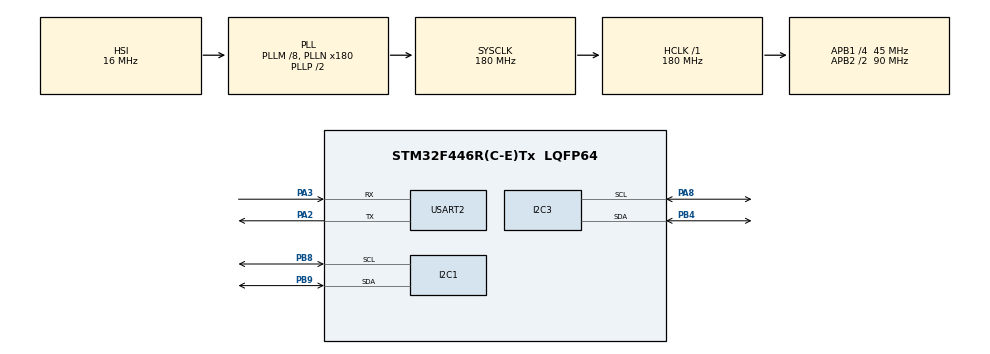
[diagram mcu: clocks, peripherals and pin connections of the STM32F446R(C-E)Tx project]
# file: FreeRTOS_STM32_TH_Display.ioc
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I2C3.I2C_Mode=I2C_Fast
Mcu.Family=STM32F4
Mcu.Name=STM32F446R(C-E)Tx
Mcu.Package=LQFP64
NVIC.PriorityGroup=NVIC_PRIORITYGROUP_4
NVIC.TIM6_DAC_IRQn=true\:15\:0\:false\:false\:true\:false\:true\:true
NVIC.TimeBase=TIM6_DAC_IRQn
NVIC.TimeBaseIP=TIM6
PA13.Mode=Serial_Wire
PA13.Signal=SYS_JTMS-SWDIO
PA14.Mode=Serial_Wire
PA14.Signal=SYS_JTCK-SWCLK
PA2.Mode=Asynchronous
PA2.Signal=USART2_TX
PA3.Mode=Asynchronous
PA3.Signal=USART2_RX
PA8.Mode=I2C
PA8.Signal=I2C3_SCL
PB4.Mode=I2C
PB4.Signal=I2C3_SDA
PB8.GPIO_Pu=GPIO_PULLUP
PB8.Mode=I2C
PB8.Signal=I2C1_SCL
PB9.GPIO_Pu=GPIO_PULLUP
PB9.Mode=I2C
PB9.Signal=I2C1_SDA
PH0-OSC_IN.Mode=HSE-External-Clock-Source
PH0-OSC_IN.Signal=RCC_OSC_IN
PH1-OSC_OUT.Mode=HSE-External-Clock-Source
PH1-OSC_OUT.Signal=RCC_OSC_OUT
ProjectManager.HeapSize=0x200
ProjectManager.StackSize=0x400
ProjectManager.TargetToolchain=STM32CubeIDE
RCC.AHBFreq_Value=180000000
RCC.APB1CLKDivider=RCC_HCLK_DIV4
RCC.APB1Freq_Value=45000000
RCC.APB1TimFreq_Value=90000000
RCC.APB2CLKDivider=RCC_HCLK_DIV2
RCC.APB2Freq_Value=90000000
RCC.APB2TimFreq_Value=180000000
RCC.CortexFreq_Value=180000000
RCC.HCLKFreq_Value=180000000
RCC.PLLM=8
RCC.PLLN=180
RCC.SYSCLKFreq_VALUE=180000000
RCC.SYSCLKSource=RCC_SYSCLKSOURCE_PLLCLK
RCC.USBFreq_Value=180000000
RCC.VCOOutputFreq_Value=360000000
USART2.VirtualMode=VM_ASYNC
VP_SYS_VS_tim6.Mode=TIM6
board=custom

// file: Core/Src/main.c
/* USER CODE BEGIN Header */
/**
  ******************************************************************************
  * @file           : main.c
  * @brief          : Main program body
  ******************************************************************************
  * @attention
  *
  * Copyright (c) 2026 STMicroelectronics.
  * All rights reserved.
  *
  * This software is licensed under terms that can be found in the LICENSE file
  * in the root directory of this software component.
  * If no LICENSE file comes with this software, it is provided AS-IS.
  *
  ******************************************************************************
  */
/* USER CODE END Header */
#include "main.h"

/* USER CODE BEGIN Includes */

#include "task_handler.h"
/* USER CODE END Includes */

/* USER CODE BEGIN PTD */
	/* Global FreeRTOS Message Queue handle shared across producer/consumer tasks */
	QueueHandle_t xSensorQueue = NULL;
/* USER CODE END PTD */

I2C_HandleTypeDef hi2c1;
I2C_HandleTypeDef hi2c3;

UART_HandleTypeDef huart2;

void SystemClock_Config(void);
static void MX_GPIO_Init(void);
static void MX_I2C1_Init(void);
static void MX_I2C3_Init(void);
static void MX_USART2_UART_Init(void);

int main(void)
{

  /* MCU Configuration--------------------------------------------------------*/

  /* Reset of all peripherals, Initializes the Flash interface and the Systick. */
  HAL_Init();

  /* Configure the system clock */
  SystemClock_Config();

  /* Initialize all configured peripherals */
  MX_GPIO_Init();
  MX_I2C1_Init();
  MX_I2C3_Init();
  MX_USART2_UART_Init();
  /* USER CODE BEGIN 2 */
  /* 1. Initialize external I2C devices (SSD1306 on I2C3, HDC1080 on I2C1)*/
  	init_OLED();
    init_HDC1080();

    /* 2. Create Message Queue capable of holding 10 SensorMsg_t items */
    xSensorQueue = xQueueCreate(10, sizeof(SensorMsg_t));
    configASSERT(xSensorQueue != NULL);

    /* 3. Create Periodic FreeRTOS Tasks:
         *    - TempTask (Priority 3): Runs 1st every 1000 ms
         *    - HumTask  (Priority 2): Runs 2nd every 1000 ms
         *    - DispTask (Priority 1): Runs 3rd every 500 ms (512 words stack for snprintf float) */
    BaseType_t status;

    status =xTaskCreate(vTempTask, "TempTask", 256, NULL, 3, NULL);
    configASSERT(status == pdPASS);

    status =xTaskCreate(vHumidityTask, "HumTask", 256, NULL, 2, NULL);
    configASSERT(status == pdPASS);

    status =xTaskCreate(vDisplayTask, "DispTask", 512, NULL, 1, NULL);
    configASSERT(status == pdPASS);

    /* Start FreeRTOS Preemptive Scheduler */
    vTaskStartScheduler();
  /* USER CODE END 2 */

  /* Infinite loop */
  while (1)
  {

  }
}

void SystemClock_Config(void)
{
  RCC_OscInitTypeDef RCC_OscInitStruct = {0};
  RCC_ClkInitTypeDef RCC_ClkInitStruct = {0};

  /** Configure the main internal regulator output voltage
  */
  __HAL_RCC_PWR_CLK_ENABLE();
  __HAL_PWR_VOLTAGESCALING_CONFIG(PWR_REGULATOR_VOLTAGE_SCALE1);

  /** Initializes the RCC Oscillators according to the specified parameters
  * in the RCC_OscInitTypeDef structure.
  */
  RCC_OscInitStruct.OscillatorType = RCC_OSCILLATORTYPE_HSI;
  RCC_OscInitStruct.HSIState = RCC_HSI_ON;
  RCC_OscInitStruct.HSICalibrationValue = RCC_HSICALIBRATION_DEFAULT;
  RCC_OscInitStruct.PLL.PLLState = RCC_PLL_ON;
  RCC_OscInitStruct.PLL.PLLSource = RCC_PLLSOURCE_HSI;
  RCC_OscInitStruct.PLL.PLLM = 8;
  RCC_OscInitStruct.PLL.PLLN = 180;
  RCC_OscInitStruct.PLL.PLLP = RCC_PLLP_DIV2;
  RCC_OscInitStruct.PLL.PLLQ = 2;
  RCC_OscInitStruct.PLL.PLLR = 2;
  if (HAL_RCC_OscConfig(&RCC_OscInitStruct) != HAL_OK)
  {
    Error_Handler();
  }

  /** Activate the Over-Drive mode
  */
  if (HAL_PWREx_EnableOverDrive() != HAL_OK)
  {
    Error_Handler();
  }

  /** Initializes the CPU, AHB and APB buses clocks
  */
  RCC_ClkInitStruct.ClockType = RCC_CLOCKTYPE_HCLK|RCC_CLOCKTYPE_SYSCLK
                              |RCC_CLOCKTYPE_PCLK1|RCC_CLOCKTYPE_PCLK2;
  RCC_ClkInitStruct.SYSCLKSource = RCC_SYSCLKSOURCE_PLLCLK;
  RCC_ClkInitStruct.AHBCLKDivider = RCC_SYSCLK_DIV1;
  RCC_ClkInitStruct.APB1CLKDivider = RCC_HCLK_DIV4;
  RCC_ClkInitStruct.APB2CLKDivider = RCC_HCLK_DIV2;

  if (HAL_RCC_ClockConfig(&RCC_ClkInitStruct, FLASH_LATENCY_5) != HAL_OK)
  {
    Error_Handler();
  }
}

static void MX_I2C1_Init(void)
{

  hi2c1.Instance = I2C1;
  hi2c1.Init.ClockSpeed = 100000;
  hi2c1.Init.DutyCycle = I2C_DUTYCYCLE_2;
  hi2c1.Init.OwnAddress1 = 0;
  hi2c1.Init.AddressingMode = I2C_ADDRESSINGMODE_7BIT;
  hi2c1.Init.DualAddressMode = I2C_DUALADDRESS_DISABLE;
  hi2c1.Init.OwnAddress2 = 0;
  hi2c1.Init.GeneralCallMode = I2C_GENERALCALL_DISABLE;
  hi2c1.Init.NoStretchMode = I2C_NOSTRETCH_DISABLE;
  if (HAL_I2C_Init(&hi2c1) != HAL_OK)
  {
    Error_Handler();
  }

}

static void MX_I2C3_Init(void)
{

  hi2c3.Instance = I2C3;
  hi2c3.Init.ClockSpeed = 400000;
  hi2c3.Init.DutyCycle = I2C_DUTYCYCLE_2;
  hi2c3.Init.OwnAddress1 = 0;
  hi2c3.Init.AddressingMode = I2C_ADDRESSINGMODE_7BIT;
  hi2c3.Init.DualAddressMode = I2C_DUALADDRESS_DISABLE;
  hi2c3.Init.OwnAddress2 = 0;
  hi2c3.Init.GeneralCallMode = I2C_GENERALCALL_DISABLE;
  hi2c3.Init.NoStretchMode = I2C_NOSTRETCH_DISABLE;
  if (HAL_I2C_Init(&hi2c3) != HAL_OK)
  {
    Error_Handler();
  }

}

static void MX_USART2_UART_Init(void)
{

  huart2.Instance = USART2;
  huart2.Init.BaudRate = 115200;
  huart2.Init.WordLength = UART_WORDLENGTH_8B;
  huart2.Init.StopBits = UART_STOPBITS_1;
  huart2.Init.Parity = UART_PARITY_NONE;
  huart2.Init.Mode = UART_MODE_TX_RX;
  huart2.Init.HwFlowCtl = UART_HWCONTROL_NONE;
  huart2.Init.OverSampling = UART_OVERSAMPLING_16;
  if (HAL_UART_Init(&huart2) != HAL_OK)
  {
    Error_Handler();
  }

}

static void MX_GPIO_Init(void)
{

  /* GPIO Ports Clock Enable */
  __HAL_RCC_GPIOH_CLK_ENABLE();
  __HAL_RCC_GPIOA_CLK_ENABLE();
  __HAL_RCC_GPIOB_CLK_ENABLE();

}

void HAL_TIM_PeriodElapsedCallback(TIM_HandleTypeDef *htim)
{
  if (htim->Instance == TIM6)
  {
    HAL_IncTick();
  }
}

void Error_Handler(void)
{
  __disable_irq();
  while (1)
  {
  }
}
